# R7FA4E10D register map
Vendor: Renesas Electronics Corporation; Series: RA4E1; File version: 1.20.00
CPU: CM33 r0p4, little endian, MPU, FPU, VTOR, 4 interrupt priority bits, 96 interrupts
Registers are 8-bit, read-write, reset 0x0 unless marked. A register's access mark holds for its fields unless they carry their own. Offsets are from the block's base; [hi:lo] are bit positions; {n}, {i} and the like mark numbered series; 'fields as' and 'values as' point back to an identical list.

## PFS — Control Register
Base 0x40080800
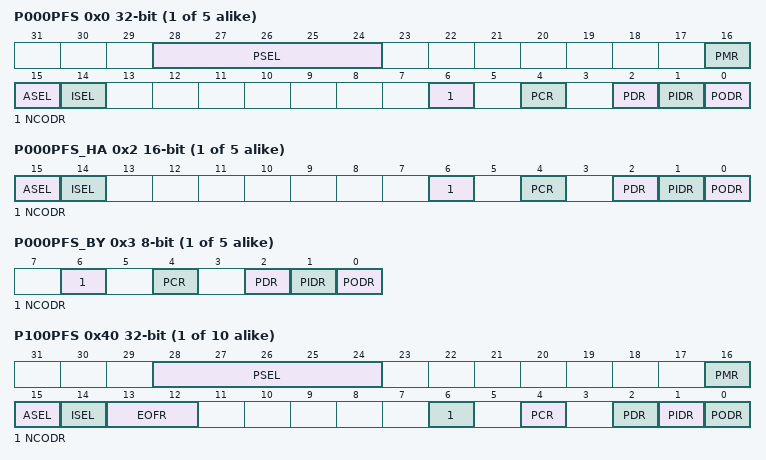
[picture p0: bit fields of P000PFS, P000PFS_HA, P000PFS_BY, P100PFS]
{0x0+4i} P00{i}PFS (i=0..4) 32-bit (reset mask 0xFFFFFFFD) — Port 00{i} Pin Function Select Register
  [28:24] PSEL — Peripheral Select
  [16] PMR — Port Mode Control
    0=Use as general I/O pin; 1=Use as I/O port for peripheral functions
  [15] ASEL — Analog Input Enable
    0=Do not use as analog pin; 1=Use as analog pin
  [14] ISEL — IRQ Input Enable
    0=Do not use as IRQn input pin; 1=Use as IRQn input pin
  [6] NCODR — N-Channel Open-Drain Control
    0=Output CMOS; 1=Output NMOS open-drain
  [4] PCR — Pull-up Control
    0=Disable input pull-up; 1=Enable input pull-up
  [2] PDR — Port Direction
    0=Input (functions as an input pin); 1=Output (functions as an output pin)
  [1] PIDR ro — Port State
    0=Low level; 1=High level
  [0] PODR — Port Output Data
    0=Output low; 1=Output high
{0x2+4i} P00{i}PFS_HA (i=0..4) 16-bit (reset mask 0xFFFD) (alternate view of P00{i}PFS) — Port 00{i} Pin Function Select Register
  [15] ASEL — Analog Input Enable
    0=Do not use as analog pin; 1=Use as analog pin
  [14] ISEL — IRQ Input Enable
    0=Do not use as IRQn input pin; 1=Use as IRQn input pin
  [6] NCODR — N-Channel Open-Drain Control
    0=Output CMOS; 1=Output NMOS open-drain
  [4] PCR — Pull-up Control
    0=Disable input pull-up; 1=Enable input pull-up
  [2] PDR — Port Direction
    values as P000PFS.PDR
  [1] PIDR ro — Port State
    0=Low level; 1=High level
  [0] PODR — Port Output Data
    0=Output low; 1=Output high
{0x3+4i} P00{i}PFS_BY (i=0..4) (reset mask 0xFD) (alternate view of P00{i}PFS) — Port 00{i} Pin Function Select Register
  [6] NCODR — N-Channel Open-Drain Control
    0=Output CMOS; 1=Output NMOS open-drain
  [4] PCR — Pull-up Control
    0=Disable input pull-up; 1=Enable input pull-up
  [2] PDR — Port Direction
    values as P000PFS.PDR
  [1] PIDR ro — Port State
    0=Low level; 1=High level
  [0] PODR — Port Output Data
    0=Output low; 1=Output high
{0x40+4i} P10{i}PFS (i=0..9) 32-bit (reset mask 0xFFFFFFFD) — Port 10{i} Pin Function Select Register
  [28:24] PSEL — Peripheral Select
  [16] PMR — Port Mode Control
    values as P000PFS.PMR
  [15] ASEL — Analog Input Enable
    0=Do not use as analog pin; 1=Use as analog pin
  [14] ISEL — IRQ Input Enable
    0=Do not use as IRQn input pin; 1=Use as IRQn input pin
  [13:12] EOFR — Event on Falling/Event on Rising
    0=Don't care; 1=Detect rising edge; 2=Detect falling edge; 3=Detect both edges
  [6] NCODR — N-Channel Open-Drain Control
    0=Output CMOS; 1=Output NMOS open-drain
  [4] PCR — Pull-up Control
    0=Disable input pull-up; 1=Enable input pull-up
  [2] PDR — Port Direction
    values as P000PFS.PDR
  [1] PIDR ro — Port State
    0=Low level; 1=High level
  [0] PODR — Port Output Data
    0=Output low; 1=Output high
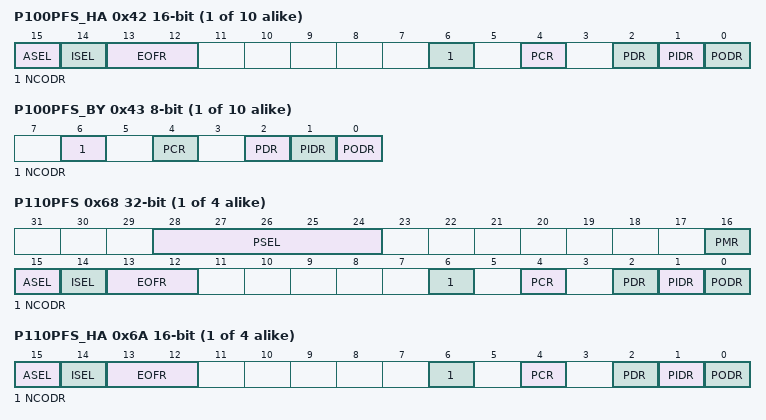
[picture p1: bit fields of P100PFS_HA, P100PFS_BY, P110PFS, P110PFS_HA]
{0x42+4i} P10{i}PFS_HA (i=0..9) 16-bit (reset mask 0xFFFD) (alternate view of P10{i}PFS) — Port 10{i} Pin Function Select Register
  [15] ASEL — Analog Input Enable
    0=Do not use as analog pin; 1=Use as analog pin
  [14] ISEL — IRQ Input Enable
    0=Do not use as IRQn input pin; 1=Use as IRQn input pin
  [13:12] EOFR — Event on Falling/Event on Rising
    values as P100PFS.EOFR
  [6] NCODR — N-Channel Open-Drain Control
    0=Output CMOS; 1=Output NMOS open-drain
  [4] PCR — Pull-up Control
    0=Disable input pull-up; 1=Enable input pull-up
  [2] PDR — Port Direction
    values as P000PFS.PDR
  [1] PIDR ro — Port State
    0=Low level; 1=High level
  [0] PODR — Port Output Data
    0=Output low; 1=Output high
{0x43+4i} P10{i}PFS_BY (i=0..9) (reset mask 0xFD) (alternate view of P10{i}PFS) — Port 10{i} Pin Function Select Register
  fields as P000PFS_BY
{0x40+4i} P1{i}PFS (i=10..13) 32-bit (reset mask 0xFFFFFFFD) — Port 1{i} Pin Function Select Register
  fields as P100PFS
{0x42+4i} P1{i}PFS_HA (i=10..13) 16-bit (reset mask 0xFFFD) (alternate view of P1{i}PFS) — Port 1{i} Pin Function Select Register
  fields as P100PFS_HA
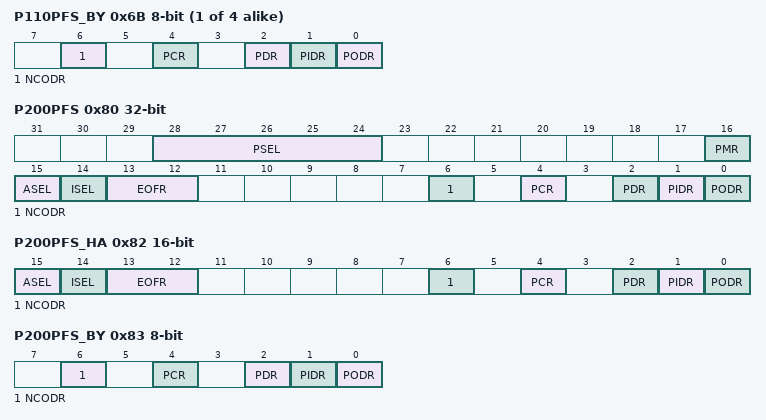
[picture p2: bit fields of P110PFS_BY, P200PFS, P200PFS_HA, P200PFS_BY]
{0x43+4i} P1{i}PFS_BY (i=10..13) (reset mask 0xFD) (alternate view of P1{i}PFS) — Port 1{i} Pin Function Select Register
  fields as P000PFS_BY
0x80 P200PFS 32-bit (reset mask 0xFFFFFFFD) — Port 1n200 Pin Function Select Register
  fields as P100PFS
0x82 P200PFS_HA 16-bit (reset mask 0xFFFD) (alternate view of P200PFS) — Port 1n200 Pin Function Select Register
  fields as P100PFS_HA
0x83 P200PFS_BY (reset mask 0xFD) (alternate view of P200PFS) — Port 1n200 Pin Function Select Register
  fields as P000PFS_BY
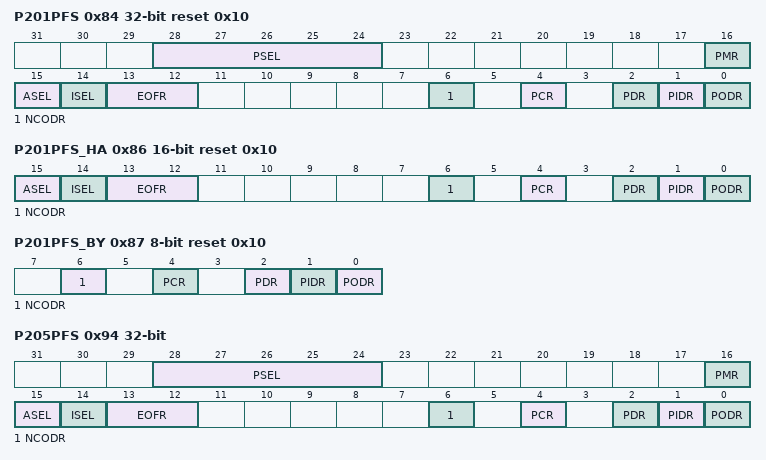
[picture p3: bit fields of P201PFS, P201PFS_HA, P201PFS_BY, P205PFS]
0x84 P201PFS 32-bit reset 0x10 (reset mask 0xFFFFFFFD) — Port 1n201 Pin Function Select Register
  fields as P100PFS
0x86 P201PFS_HA 16-bit reset 0x10 (reset mask 0xFFFD) (alternate view of P201PFS) — Port 1n201 Pin Function Select Register
  fields as P100PFS_HA
0x87 P201PFS_BY reset 0x10 (reset mask 0xFD) (alternate view of P201PFS) — Port 1n201 Pin Function Select Register
  fields as P000PFS_BY
0x94 P205PFS 32-bit (reset mask 0xFFFFFFFD) — Port 1n205 Pin Function Select Register
  fields as P100PFS
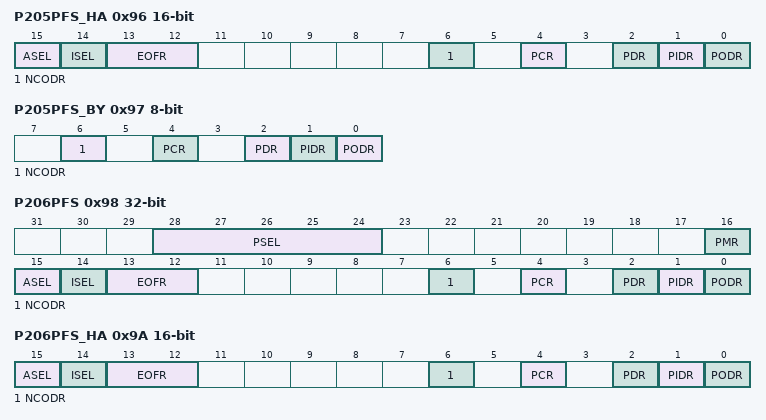
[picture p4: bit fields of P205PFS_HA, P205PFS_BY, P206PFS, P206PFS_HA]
0x96 P205PFS_HA 16-bit (reset mask 0xFFFD) (alternate view of P205PFS) — Port 1n205 Pin Function Select Register
  fields as P100PFS_HA
0x97 P205PFS_BY (reset mask 0xFD) (alternate view of P205PFS) — Port 1n205 Pin Function Select Register
  fields as P000PFS_BY
0x98 P206PFS 32-bit (reset mask 0xFFFFFFFD) — Port 1n206 Pin Function Select Register
  fields as P100PFS
0x9A P206PFS_HA 16-bit (reset mask 0xFFFD) (alternate view of P206PFS) — Port 1n206 Pin Function Select Register
  fields as P100PFS_HA
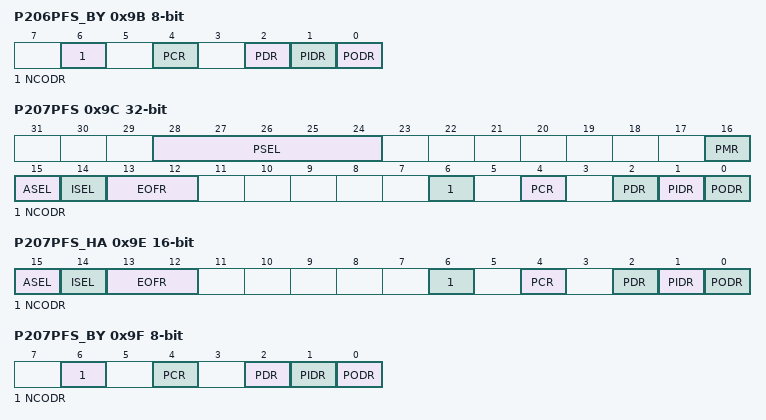
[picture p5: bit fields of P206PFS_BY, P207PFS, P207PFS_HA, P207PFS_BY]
0x9B P206PFS_BY (reset mask 0xFD) (alternate view of P206PFS) — Port 1n206 Pin Function Select Register
  fields as P000PFS_BY
0x9C P207PFS 32-bit (reset mask 0xFFFFFFFD) — Port 1n207 Pin Function Select Register
  fields as P100PFS
0x9E P207PFS_HA 16-bit (reset mask 0xFFFD) (alternate view of P207PFS) — Port 1n207 Pin Function Select Register
  fields as P100PFS_HA
0x9F P207PFS_BY (reset mask 0xFD) (alternate view of P207PFS) — Port 1n207 Pin Function Select Register
  fields as P000PFS_BY
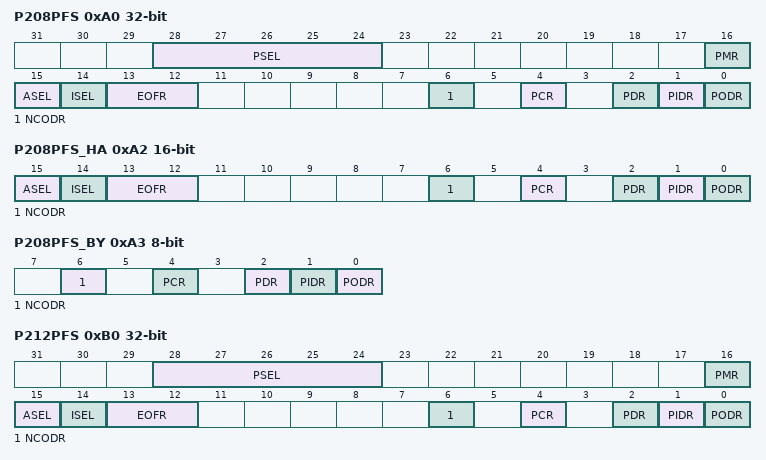
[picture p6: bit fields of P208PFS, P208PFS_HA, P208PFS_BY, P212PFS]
0xA0 P208PFS 32-bit (reset mask 0xFFFFFFFD) — Port 1n208 Pin Function Select Register
  fields as P100PFS
0xA2 P208PFS_HA 16-bit (reset mask 0xFFFD) (alternate view of P208PFS) — Port 1n208 Pin Function Select Register
  fields as P100PFS_HA
0xA3 P208PFS_BY (reset mask 0xFD) (alternate view of P208PFS) — Port 1n208 Pin Function Select Register
  fields as P000PFS_BY
0xB0 P212PFS 32-bit (reset mask 0xFFFFFFFD) — Port 1n212 Pin Function Select Register
  fields as P100PFS
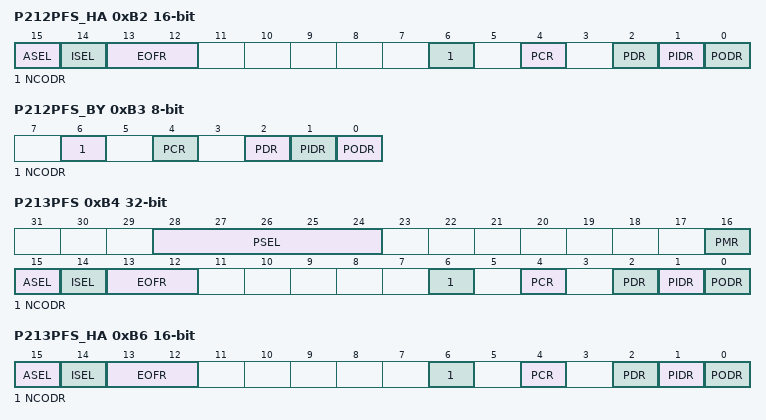
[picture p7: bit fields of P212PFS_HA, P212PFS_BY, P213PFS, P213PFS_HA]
0xB2 P212PFS_HA 16-bit (reset mask 0xFFFD) (alternate view of P212PFS) — Port 1n212 Pin Function Select Register
  fields as P100PFS_HA
0xB3 P212PFS_BY (reset mask 0xFD) (alternate view of P212PFS) — Port 1n212 Pin Function Select Register
  fields as P000PFS_BY
0xB4 P213PFS 32-bit (reset mask 0xFFFFFFFD) — Port 1n213 Pin Function Select Register
  fields as P100PFS
0xB6 P213PFS_HA 16-bit (reset mask 0xFFFD) (alternate view of P213PFS) — Port 1n213 Pin Function Select Register
  fields as P100PFS_HA
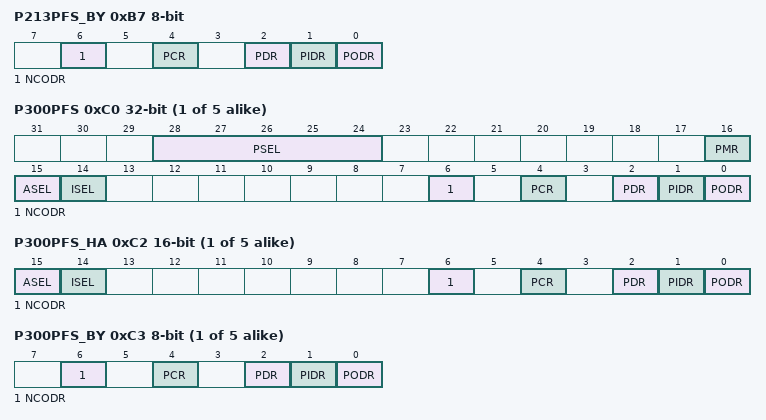
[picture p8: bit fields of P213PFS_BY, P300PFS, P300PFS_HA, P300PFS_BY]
0xB7 P213PFS_BY (reset mask 0xFD) (alternate view of P213PFS) — Port 1n213 Pin Function Select Register
  fields as P000PFS_BY
{0xC0+4i} P30{i}PFS (i=0..4) 32-bit (reset mask 0xFFFFFFFD) — Port 30{i} Pin Function Select Register
  fields as P000PFS
{0xC2+4i} P30{i}PFS_HA (i=0..4) 16-bit (reset mask 0xFFFD) (alternate view of P30{i}PFS) — Port 30{i} Pin Function Select Register
  fields as P000PFS_HA
{0xC3+4i} P30{i}PFS_BY (i=0..4) (reset mask 0xFD) (alternate view of P30{i}PFS) — Port 30{i} Pin Function Select Register
  fields as P000PFS_BY
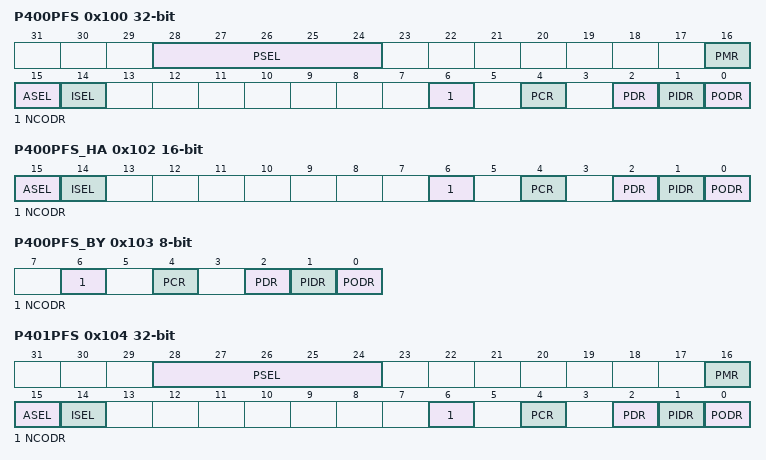
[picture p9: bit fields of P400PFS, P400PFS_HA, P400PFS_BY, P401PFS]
0x100 P400PFS 32-bit (reset mask 0xFFFFFFFD) — Port 400 Pin Function Select Register
  fields as P000PFS
0x102 P400PFS_HA 16-bit (reset mask 0xFFFD) (alternate view of P400PFS) — Port 400 Pin Function Select Register
  fields as P000PFS_HA
0x103 P400PFS_BY (reset mask 0xFD) (alternate view of P400PFS) — Port 400 Pin Function Select Register
  fields as P000PFS_BY
0x104 P401PFS 32-bit (reset mask 0xFFFFFFFD) — Port 401 Pin Function Select Register
  fields as P000PFS
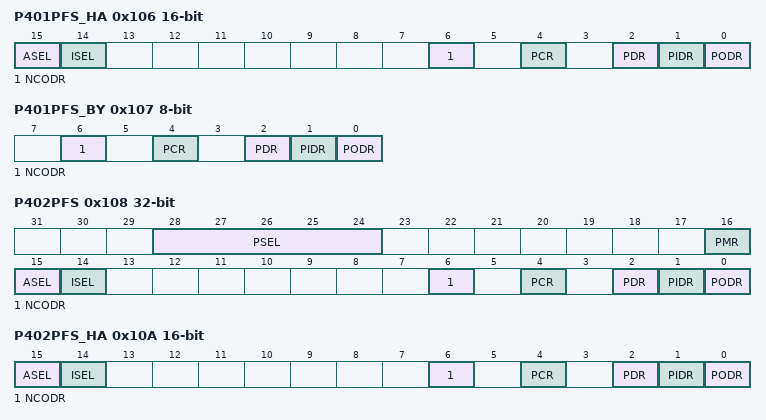
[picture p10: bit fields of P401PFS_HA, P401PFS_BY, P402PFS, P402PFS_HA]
0x106 P401PFS_HA 16-bit (reset mask 0xFFFD) (alternate view of P401PFS) — Port 401 Pin Function Select Register
  fields as P000PFS_HA
0x107 P401PFS_BY (reset mask 0xFD) (alternate view of P401PFS) — Port 401 Pin Function Select Register
  fields as P000PFS_BY
0x108 P402PFS 32-bit (reset mask 0xFFFFFFFD) — Port 402 Pin Function Select Register
  fields as P000PFS
0x10A P402PFS_HA 16-bit (reset mask 0xFFFD) (alternate view of P402PFS) — Port 402 Pin Function Select Register
  fields as P000PFS_HA
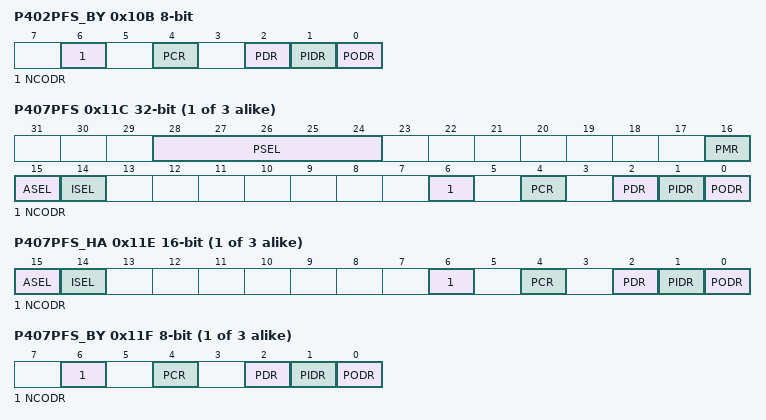
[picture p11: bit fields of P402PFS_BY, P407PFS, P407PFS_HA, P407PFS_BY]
0x10B P402PFS_BY (reset mask 0xFD) (alternate view of P402PFS) — Port 402 Pin Function Select Register
  fields as P000PFS_BY
{0x100+4i} P40{i}PFS (i=7..9) 32-bit (reset mask 0xFFFFFFFD) — Port 40{i} Pin Function Select Register
  fields as P000PFS
{0x102+4i} P40{i}PFS_HA (i=7..9) 16-bit (reset mask 0xFFFD) (alternate view of P40{i}PFS) — Port 40{i} Pin Function Select Register
  fields as P000PFS_HA
{0x103+4i} P40{i}PFS_BY (i=7..9) (reset mask 0xFD) (alternate view of P40{i}PFS) — Port 40{i} Pin Function Select Register
  fields as P000PFS_BY
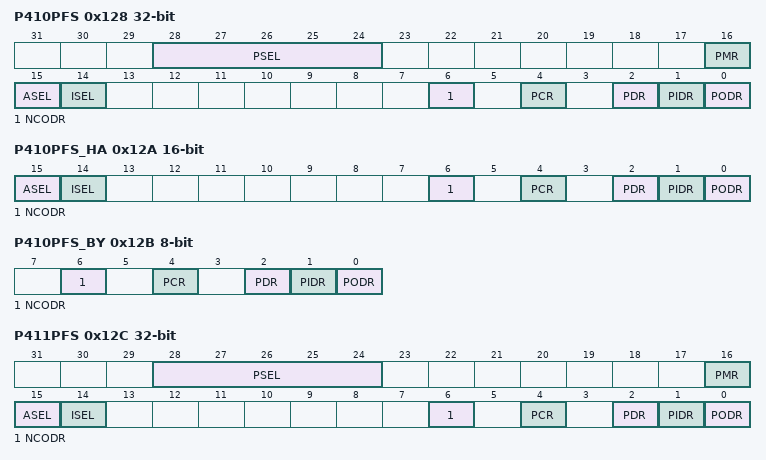
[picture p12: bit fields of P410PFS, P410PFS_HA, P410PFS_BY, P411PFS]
0x128 P410PFS 32-bit (reset mask 0xFFFFFFFD) — Port 410 Pin Function Select Register
  fields as P000PFS
0x12A P410PFS_HA 16-bit (reset mask 0xFFFD) (alternate view of P410PFS) — Port 410 Pin Function Select Register
  fields as P000PFS_HA
0x12B P410PFS_BY (reset mask 0xFD) (alternate view of P410PFS) — Port 410 Pin Function Select Register
  fields as P000PFS_BY
0x12C P411PFS 32-bit (reset mask 0xFFFFFFFD) — Port 411 Pin Function Select Register
  fields as P000PFS
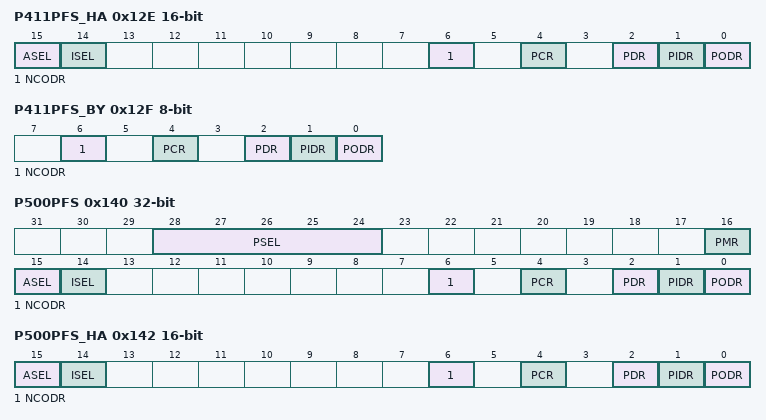
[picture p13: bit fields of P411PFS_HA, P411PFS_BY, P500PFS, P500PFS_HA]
0x12E P411PFS_HA 16-bit (reset mask 0xFFFD) (alternate view of P411PFS) — Port 411 Pin Function Select Register
  fields as P000PFS_HA
0x12F P411PFS_BY (reset mask 0xFD) (alternate view of P411PFS) — Port 411 Pin Function Select Register
  fields as P000PFS_BY
0x140 P500PFS 32-bit (reset mask 0xFFFFFFFD) — Port 500 Pin Function Select Register
  fields as P000PFS
0x142 P500PFS_HA 16-bit (reset mask 0xFFFD) (alternate view of P500PFS) — Port 500 Pin Function Select Register
  fields as P000PFS_HA
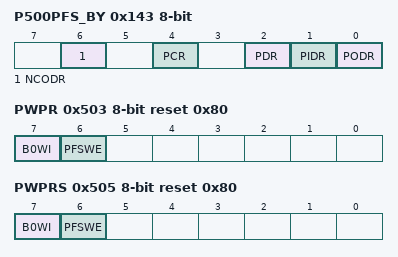
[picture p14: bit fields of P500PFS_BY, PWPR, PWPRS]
0x143 P500PFS_BY (reset mask 0xFD) (alternate view of P500PFS) — Port 500 Pin Function Select Register
  fields as P000PFS_BY
0x503 PWPR reset 0x80 — Write-Protect Register
  [7] B0WI — PFSWE Bit Write Disable
    0=Writing to the PFSWE bit is enabled; 1=Writing to the PFSWE bit is disabled
  [6] PFSWE — PmnPFS Register Write Enable
    0=Writing to the PmnPFS register is disabled; 1=Writing to the PmnPFS register is enabled
0x505 PWPRS reset 0x80 — Write-Protect Register for Secure
  [7] B0WI — PFSWE Bit Write Disable
    0=Enable writes the PFSWE bit; 1=Disable writes to the PFSWE bit
  [6] PFSWE — PmnPFS Register Write Enable
    0=Disable writes to the PmnPFS register; 1=Enable writes to the PmnPFS register
{0x510+2i} P{i}SAR (i=0..5) 16-bit reset 0xFFFF — Port Security Attribution register
  [15:0] PMNSA — Pmn Security Attribution
    0=Secure; 1=Non Secure
